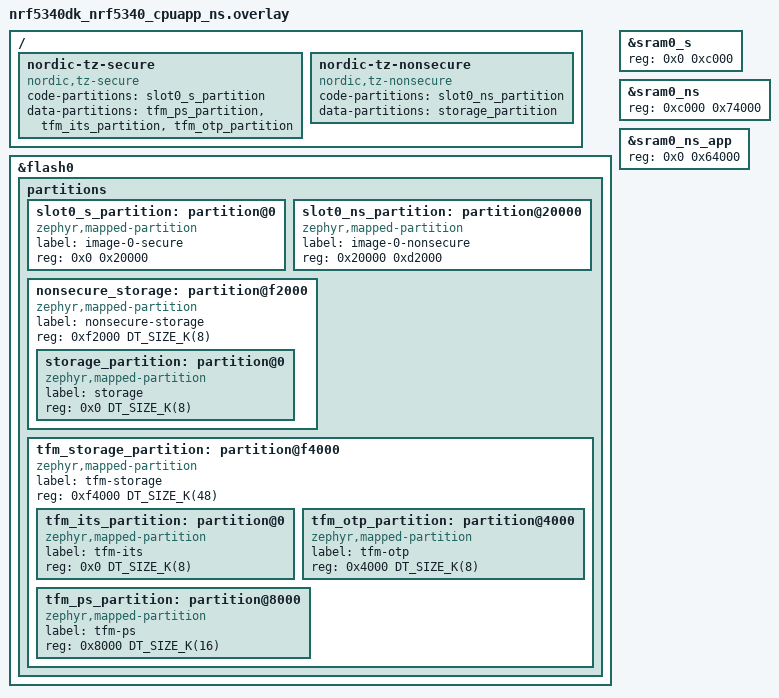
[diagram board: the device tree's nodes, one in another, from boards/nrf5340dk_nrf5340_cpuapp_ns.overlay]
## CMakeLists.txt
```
#
# Copyright (c) 2018 Nordic Semiconductor
#
# SPDX-License-Identifier: LicenseRef-Nordic-5-Clause
#
cmake_minimum_required(VERSION 3.20.0)

find_package(Zephyr REQUIRED HINTS $ENV{ZEPHYR_BASE})
project(NONE)

# NORDIC SDK APP START
target_sources(app PRIVATE
  src/main.c
)

# NORDIC SDK APP END
```

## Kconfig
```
#
# Copyright (c) 2018 Nordic Semiconductor
#
# SPDX-License-Identifier: LicenseRef-Nordic-5-Clause
#

source "Kconfig.zephyr"

menu "Nordic LED-Button BLE GATT service sample"

config BT_LBS_SECURITY_ENABLED
	bool "Enable security"
	default y
	select BT_SMP
	select BT_SETTINGS
	select FLASH
	select FLASH_PAGE_LAYOUT
	select FLASH_MAP
	select ZMS if (SOC_FLASH_NRF_RRAM || SOC_FLASH_NRF_MRAM)
	select NVS if !(SOC_FLASH_NRF_RRAM || SOC_FLASH_NRF_MRAM)
	select SETTINGS
	help
	  "Enable BLE security for the LED-Button service"

endmenu
```

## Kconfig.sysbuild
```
#
# Copyright (c) 2023 Nordic Semiconductor
#
# SPDX-License-Identifier: LicenseRef-Nordic-5-Clause
#

config PARTITION_MANAGER
	default y if BOARD_THINGY53

config NRF_RADIO_LOADER
	default y if SOC_NRF54H20

config NRF_DEFAULT_IPC_RADIO
	default y

config NETCORE_IPC_RADIO_BT_HCI_IPC
	default y

source "share/sysbuild/Kconfig"
```

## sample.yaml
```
sample:
  description: Bluetooth Low Energy LED Button service sample
  name: Bluetooth LE LED Button service

common:
  sysbuild: true
  build_only: true
  tags:
    - bluetooth
    - ci_build
    - sysbuild
    - ci_samples_bluetooth

tests:
  sample.bluetooth.peripheral_lbs:
    build_only: false
    platform_allow: &peripheral_lbs_platforms
      - nrf5340dk/nrf5340/cpuapp
      - nrf5340dk/nrf5340/cpuapp/ns
      - nrf54h20dk/nrf54h20/cpuapp
      - nrf54l15dk/nrf54l05/cpuapp
      - nrf54l15dk/nrf54l10/cpuapp
      - nrf54l15dk/nrf54l15/cpuapp
      - nrf54l15dk/nrf54l15/cpuapp/ns
      - nrf54lm20dk/nrf54lm20a/cpuapp
      - nrf54lm20dk/nrf54lm20a/cpuapp/ns
      - nrf54lm20dk/nrf54lm20b/cpuapp
      - nrf54lm20dk/nrf54lm20b/cpuapp/ns
      - nrf54lv10dk/nrf54lv10a/cpuapp
      - nrf54lv10dk/nrf54lv10a/cpuapp/ns
      - nrf54lc10dk/nrf54lc10a/cpuapp
      - nrf54lc10dk/nrf54lc10a/cpuapp/ns
      - nrf54ls05dk/nrf54ls05a/cpuapp
      - nrf54ls05dk/nrf54ls05b/cpuapp
      - nrf7120dk/nrf7120/cpuapp
    integration_platforms: *peripheral_lbs_platforms
    harness: console
    harness_config:
      type: multi_line
      ordered: true
      regex:
        - "Starting Bluetooth Peripheral LBS sample"
        - "Bluetooth initialized"
        - "Advertising successfully started"
    timeout: 15

  sample.bluetooth.peripheral_lbs_minimal:
    platform_allow:
      - nrf54ls05dk/nrf54ls05a/cpuapp
    integration_platforms:
      - nrf54ls05dk/nrf54ls05a/cpuapp
    extra_args: FILE_SUFFIX=minimal

  sample.bluetooth.peripheral_lbs_no_security:
    platform_allow: *peripheral_lbs_platforms
    integration_platforms:
      - nrf54l15dk/nrf54l15/cpuapp
    extra_args: CONFIG_BT_LBS_SECURITY_ENABLED=n

  sample.bluetooth.peripheral_lbs_bt_ota_dfu:
    build_only: true
    platform_allow:
      - nrf5340dk/nrf5340/cpuapp
      - nrf5340dk/nrf5340/cpuapp/ns
      - nrf54l15dk/nrf54l05/cpuapp
      - nrf54l15dk/nrf54l10/cpuapp
      - nrf54l15dk/nrf54l15/cpuapp
      - nrf54l15dk/nrf54l15/cpuapp/ns
      - nrf54lm20dk/nrf54lm20a/cpuapp
      - nrf54lm20dk/nrf54lm20a/cpuapp/ns
      - nrf54lm20dk/nrf54lm20b/cpuapp
      - nrf54lm20dk/nrf54lm20b/cpuapp/ns
      - nrf54lv10dk/nrf54lv10a/cpuapp
      - nrf54lv10dk/nrf54lv10a/cpuapp/ns
      - nrf54lc10dk/nrf54lc10a/cpuapp
      - nrf54lc10dk/nrf54lc10a/cpuapp/ns
      - nrf54ls05dk/nrf54ls05a/cpuapp
      - nrf54ls05dk/nrf54ls05b/cpuapp
    integration_platforms:
      - nrf5340dk/nrf5340/cpuapp
      - nrf54l15dk/nrf54l05/cpuapp
      - nrf54l15dk/nrf54l10/cpuapp
      - nrf54l15dk/nrf54l15/cpuapp
      - nrf54l15dk/nrf54l15/cpuapp/ns
      - nrf54lm20dk/nrf54lm20a/cpuapp
      - nrf54lm20dk/nrf54lm20a/cpuapp/ns
      - nrf54lm20dk/nrf54lm20b/cpuapp
      - nrf54lm20dk/nrf54lm20b/cpuapp/ns
      - nrf54lv10dk/nrf54lv10a/cpuapp
      - nrf54lv10dk/nrf54lv10a/cpuapp/ns
      - nrf54lc10dk/nrf54lc10a/cpuapp
      - nrf54lc10dk/nrf54lc10a/cpuapp/ns
      - nrf54ls05dk/nrf54ls05a/cpuapp
      - nrf54ls05dk/nrf54ls05b/cpuapp
    extra_configs:
      - CONFIG_BOOTLOADER_MCUBOOT=y
      - CONFIG_NCS_SAMPLE_MCUMGR_BT_OTA_DFU=y

  sample.bluetooth.peripheral_lbs_bt_ota_dfu.direct_xip:
    build_only: true
    platform_allow:
      - nrf54l15dk/nrf54l15/cpuapp
    integration_platforms:
      - nrf54l15dk/nrf54l15/cpuapp
    extra_args: mcuboot_CONFIG_BOOT_DIRECT_XIP=y
    extra_configs:
      - CONFIG_BOOTLOADER_MCUBOOT=y
      - CONFIG_NCS_SAMPLE_MCUMGR_BT_OTA_DFU=y
      - CONFIG_MCUBOOT_BOOTLOADER_MODE_DIRECT_XIP=y

  sample.bluetooth.peripheral_lbs_bt_ota_dfu.direct_xip.revert:
    build_only: true
    platform_allow:
      - nrf54l15dk/nrf54l15/cpuapp
    integration_platforms:
      - nrf54l15dk/nrf54l15/cpuapp
    extra_args:
      - mcuboot_CONFIG_BOOT_DIRECT_XIP=y
      - mcuboot_CONFIG_BOOT_DIRECT_XIP_REVERT=y
    extra_configs:
      - CONFIG_BOOTLOADER_MCUBOOT=y
      - CONFIG_NCS_SAMPLE_MCUMGR_BT_OTA_DFU=y
      - CONFIG_MCUBOOT_BOOTLOADER_MODE_DIRECT_XIP_WITH_REVERT=y

  sample.bluetooth.peripheral_lbs.llvm:
    toolchain_allow: llvm
    platform_allow:
      - nrf54l15dk/nrf54l15/cpuapp
      - nrf54l15dk/nrf54l15/cpuapp/ns
      - nrf54lm20dk/nrf54lm20a/cpuapp
      - nrf54lm20dk/nrf54lm20a/cpuapp/ns
      - nrf54lm20dk/nrf54lm20b/cpuapp
      - nrf54lm20dk/nrf54lm20b/cpuapp/ns
      - nrf54lv10dk/nrf54lv10a/cpuapp
      - nrf54lc10dk/nrf54lc10a/cpuapp
      - nrf54ls05dk/nrf54ls05a/cpuapp
      - nrf54ls05dk/nrf54ls05b/cpuapp
    integration_platforms:
      - nrf54l15dk/nrf54l15/cpuapp
      - nrf54l15dk/nrf54l15/cpuapp/ns
      - nrf54lm20dk/nrf54lm20a/cpuapp
      - nrf54lm20dk/nrf54lm20a/cpuapp/ns
      - nrf54lm20dk/nrf54lm20b/cpuapp
      - nrf54lm20dk/nrf54lm20b/cpuapp/ns
      - nrf54lv10dk/nrf54lv10a/cpuapp
      - nrf54lc10dk/nrf54lc10a/cpuapp
      - nrf54ls05dk/nrf54ls05a/cpuapp
      - nrf54ls05dk/nrf54ls05b/cpuapp
    tags:
      - bluetooth
      - ci_build
      - sysbuild

  sample.bluetooth.peripheral_lbs.l15_tag:
    integration_platforms:
      - nrf54l15tag/nrf54l15/cpuapp
    platform_allow:
      - nrf54l15tag/nrf54l15/cpuapp
    extra_configs:
      - CONFIG_NCS_SAMPLE_MCUMGR_BT_OTA_DFU=y
      - CONFIG_LOG_BACKEND_UART=n
      - CONFIG_UART_CONSOLE=n
      - CONFIG_USE_SEGGER_RTT=y
      - CONFIG_LOG_BACKEND_RTT=y
      - CONFIG_LOG_MODE_DEFERRED=y
      - CONFIG_LOG_BACKEND_UART=n
      - CONFIG_SEGGER_RTT_MAX_NUM_UP_BUFFERS=5
      - CONFIG_SEGGER_RTT_MAX_NUM_DOWN_BUFFERS=5
      - CONFIG_SEGGER_RTT_BUFFER_SIZE_UP=2048
      - CONFIG_SEGGER_RTT_BUFFER_SIZE_DOWN=32
      - CONFIG_SEGGER_RTT_PRINTF_BUFFER_SIZE=128
    extra_args:
      - SB_CONFIG_BOOTLOADER_MCUBOOT=y
      - mcuboot_CONFIG_LOG_BACKEND_UART=n
      - mcuboot_CONFIG_UART_CONSOLE=n
      - mcuboot_CONFIG_USE_SEGGER_RTT=y
      - mcuboot_CONFIG_LOG_BACKEND_RTT=y
      - mcuboot_CONFIG_LOG_MODE_IMMEDIATE=y
      - mcuboot_CONFIG_LOG_BACKEND_UART=n
```

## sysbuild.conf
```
#
# Copyright (c) 2024 Nordic Semiconductor
#
# SPDX-License-Identifier: LicenseRef-Nordic-5-Clause
#

SB_CONFIG_BT=y
#SB_CONFIG_BT_RPC
#SB_CONFIG_IEEE802154

#SB_CONFIG_NETCORE_IPC_RADIO_CUSTOM_CONF
#SB_CONFIG_NETCORE_IPC_RADIO_DEBUG
```

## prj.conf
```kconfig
#
# Copyright (c) 2018 Nordic Semiconductor
#
# SPDX-License-Identifier: LicenseRef-Nordic-5-Clause
#
CONFIG_NCS_SAMPLES_DEFAULTS=y

CONFIG_BT=y
CONFIG_BT_PERIPHERAL=y
CONFIG_BT_DEVICE_NAME="Nordic_LBS"

# Enable the LBS service
CONFIG_BT_LBS=y
CONFIG_BT_LBS_POLL_BUTTON=y
CONFIG_DK_LIBRARY=y

CONFIG_SYSTEM_WORKQUEUE_STACK_SIZE=2048

# Enable old clock_control_nrf api implementation for mpsl to use
CONFIG_CLOCK_CONTROL_NRF=y
```

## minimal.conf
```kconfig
# BEGIN Configurations from basic/minimal
# Drivers and peripherals
CONFIG_I2C=n
CONFIG_WATCHDOG=n
CONFIG_GPIO=n
CONFIG_PINMUX=n
CONFIG_SPI=n
CONFIG_SERIAL=n

# Power management
CONFIG_PM=n

# Interrupts
CONFIG_DYNAMIC_INTERRUPTS=n
CONFIG_IRQ_OFFLOAD=n

# Memory protection
CONFIG_THREAD_STACK_INFO=n
CONFIG_THREAD_CUSTOM_DATA=n
CONFIG_FPU=n

# Boot
CONFIG_BOOT_BANNER=n
CONFIG_BOOT_DELAY=0

# Console
CONFIG_CONSOLE=n
CONFIG_UART_CONSOLE=n
CONFIG_STDOUT_CONSOLE=n
CONFIG_PRINTK=n
CONFIG_EARLY_CONSOLE=n

# Build
CONFIG_SIZE_OPTIMIZATIONS=y

# ARM
CONFIG_ARM_MPU=n
# END Configurations from basic/minimal

# In order to correctly tune the stack sizes for the threads the following
# Configurations can enabled to print the current use:
# CONFIG_THREAD_NAME=y
# CONFIG_THREAD_ANALYZER=y
# CONFIG_THREAD_ANALYZER_AUTO=y
# CONFIG_THREAD_ANALYZER_RUN_UNLOCKED=y
# CONFIG_THREAD_ANALYZER_USE_PRINTK=y
# CONFIG_CONSOLE=y
# CONFIG_UART_CONSOLE=y
# CONFIG_SERIAL=y
# CONFIG_PRINTK=y

# Example output of thread analyzer
# SDC RX              : unused 816 usage 208 / 1024 (20 %)
# BT RX               : unused 1784 usage 416 / 2200 (18 %)
# BT TX               : unused 992 usage 544 / 1536 (35 %)
# thread_analyzer     : unused 136 usage 376 / 512 (73 %)
# sysworkq            : unused 1824 usage 224 / 2048 (10 %)
# MPSL signal         : unused 520 usage 504 / 1024 (49 %)
# idle 00             : unused 192 usage 64 / 256 (25 %)
# main                : unused 136 usage 888 / 1024 (86 %)
# Configurations set based on thread analyzer output.
CONFIG_SDC_RX_STACK_SIZE=324
CONFIG_BT_RX_STACK_SIZE=1024
CONFIG_BT_HCI_TX_STACK_SIZE_WITH_PROMPT=y
CONFIG_BT_HCI_TX_STACK_SIZE=640
CONFIG_SYSTEM_WORKQUEUE_STACK_SIZE=256
CONFIG_MPSL_SIGNAL_STACK_SIZE=640
CONFIG_MAIN_STACK_SIZE=1024
CONFIG_IDLE_STACK_SIZE=128
CONFIG_ISR_STACK_SIZE=1024

# Disable features not needed
CONFIG_TIMESLICING=n
CONFIG_MINIMAL_LIBC_MALLOC=n
CONFIG_LOG=n
CONFIG_ASSERT=n

# Disable Bluetooth features not needed
CONFIG_BT_DEBUG_NONE=y
CONFIG_BT_ASSERT=n
CONFIG_BT_DATA_LEN_UPDATE=n
CONFIG_BT_PHY_UPDATE=n
CONFIG_BT_GATT_CACHING=n
CONFIG_BT_GATT_SERVICE_CHANGED=n
CONFIG_BT_GAP_PERIPHERAL_PREF_PARAMS=n
CONFIG_BT_SETTINGS_CCC_LAZY_LOADING=y
CONFIG_BT_HCI_VS_EXT=n

# Disable Bluetooth controller features not needed
CONFIG_BT_CTLR_PRIVACY=n
CONFIG_BT_CTLR_PHY_2M=n

# Reduce Bluetooth buffers
CONFIG_BT_DISCARDABLE_BUF_COUNT=1
CONFIG_BT_DISCARDABLE_BUF_SIZE=45
CONFIG_BT_RX_BUF_COUNT=2

CONFIG_BT_CONN_TX_MAX=2
CONFIG_BT_L2CAP_TX_BUF_COUNT=2
CONFIG_BT_ATT_TX_MAX=1
CONFIG_BT_CTLR_RX_BUFFERS=1
CONFIG_BT_CTLR_TX_BUFFERS=3
CONFIG_BT_CTLR_TX_BUFFER_SIZE=27
```

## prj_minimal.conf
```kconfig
# BEGIN Configurations from basic/minimal

CONFIG_NCS_SAMPLES_DEFAULTS=y

CONFIG_BT=y
CONFIG_BT_PERIPHERAL=y
CONFIG_BT_DEVICE_NAME="Nordic_LBS"

# Enable the LBS service
CONFIG_BT_LBS=y
CONFIG_BT_LBS_POLL_BUTTON=y
CONFIG_DK_LIBRARY=y

# Drivers and peripherals
CONFIG_I2C=n
CONFIG_WATCHDOG=n
CONFIG_GPIO=n
CONFIG_SPI=n
CONFIG_SERIAL=n

# Power management

# Interrupts
CONFIG_DYNAMIC_INTERRUPTS=n
CONFIG_IRQ_OFFLOAD=n

# Memory protection
CONFIG_THREAD_STACK_INFO=n
CONFIG_THREAD_CUSTOM_DATA=n
CONFIG_FPU=n

# Boot
CONFIG_NCS_BOOT_BANNER=n
CONFIG_BOOT_BANNER=n
CONFIG_BOOT_DELAY=0

# Console
CONFIG_CONSOLE=n
CONFIG_UART_CONSOLE=n
CONFIG_STDOUT_CONSOLE=n
CONFIG_PRINTK=n
CONFIG_EARLY_CONSOLE=n

# Build
CONFIG_SIZE_OPTIMIZATIONS=y

# ARM
CONFIG_ARM_MPU=n
# END Configurations from basic/minimal

# In order to correctly tune the stack sizes for the threads the following
# Configurations can enabled to print the current use:
# CONFIG_THREAD_NAME=y
# CONFIG_THREAD_ANALYZER=y
# CONFIG_THREAD_ANALYZER_AUTO=y
# CONFIG_THREAD_ANALYZER_RUN_UNLOCKED=y
# CONFIG_THREAD_ANALYZER_USE_PRINTK=y
# CONFIG_CONSOLE=y
# CONFIG_UART_CONSOLE=y
# CONFIG_SERIAL=y
# CONFIG_PRINTK=y

# Example output of thread analyzer
# SDC RX              : unused 816 usage 208 / 1024 (20 %)
# BT RX               : unused 1784 usage 416 / 2200 (18 %)
# BT TX               : unused 992 usage 544 / 1536 (35 %)
# thread_analyzer     : unused 136 usage 376 / 512 (73 %)
# sysworkq            : unused 1824 usage 224 / 2048 (10 %)
# MPSL signal         : unused 520 usage 504 / 1024 (49 %)
# idle 00             : unused 192 usage 64 / 256 (25 %)
# main                : unused 136 usage 888 / 1024 (86 %)
# Configurations set based on thread analyzer output.
CONFIG_BT_RX_STACK_SIZE=1024
CONFIG_BT_HCI_TX_STACK_SIZE_WITH_PROMPT=y
CONFIG_BT_HCI_TX_STACK_SIZE=640
CONFIG_SYSTEM_WORKQUEUE_STACK_SIZE=1536
CONFIG_MPSL_WORK_STACK_SIZE=640
CONFIG_IDLE_STACK_SIZE=128
CONFIG_ISR_STACK_SIZE=1024

# Disable features not needed
CONFIG_TIMESLICING=n
CONFIG_COMMON_LIBC_MALLOC=n
CONFIG_LOG=n
CONFIG_ASSERT=n

# Disable Bluetooth features not needed
CONFIG_BT_DEBUG_NONE=y
CONFIG_BT_ASSERT=n
CONFIG_BT_DATA_LEN_UPDATE=n
CONFIG_BT_PHY_UPDATE=n
CONFIG_BT_GATT_CACHING=n
CONFIG_BT_GATT_SERVICE_CHANGED=n
CONFIG_BT_GAP_PERIPHERAL_PREF_PARAMS=n
CONFIG_BT_SETTINGS_CCC_LAZY_LOADING=y
CONFIG_BT_HCI_VS=n

# Disable Bluetooth controller features not needed
CONFIG_BT_CTLR_PRIVACY=n
CONFIG_BT_CTLR_PHY_2M=n

# Reduce Bluetooth buffers
CONFIG_BT_BUF_EVT_DISCARDABLE_COUNT=1
CONFIG_BT_BUF_EVT_DISCARDABLE_SIZE=43
CONFIG_BT_BUF_EVT_RX_COUNT=2

CONFIG_BT_L2CAP_TX_BUF_COUNT=2
CONFIG_BT_ATT_TX_COUNT=2
CONFIG_BT_BUF_EVT_RX_COUNT=4
CONFIG_BT_BUF_ACL_TX_COUNT=3
CONFIG_BT_BUF_ACL_TX_SIZE=27
```

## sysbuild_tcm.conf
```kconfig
#
# Copyright (c) 2025 Nordic Semiconductor ASA
#
# SPDX-License-Identifier: LicenseRef-Nordic-5-Clause
#

# ipc_radio in cpurad TCM via radio_loader; no MCUboot (no signed merge, no DFU).
SB_CONFIG_LBS_IPC_RADIO_TCM=y
SB_CONFIG_NETCORE_REMOTE=y
SB_CONFIG_NRF_RADIO_LOADER=y

SB_CONFIG_BOOTLOADER_NONE=y
SB_CONFIG_BOOTLOADER_MCUBOOT=n
```

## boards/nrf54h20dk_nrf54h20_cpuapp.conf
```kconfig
#
# Copyright (c) 2025 Nordic Semiconductor ASA
#
# SPDX-License-Identifier: LicenseRef-Nordic-5-Clause
#

# Enable device power management
CONFIG_PM_DEVICE=y
CONFIG_PM_DEVICE_RUNTIME=y

# Enable system power management
CONFIG_PM=y

# Enable power off state
CONFIG_POWEROFF=y

# Enable cpurad for sysbuild
CONFIG_SOC_NRF54H20_CPURAD_ENABLE=y

# MRAM latency optimization - allow MRAM to power off when idle
# This reduces power consumption by allowing MRAM power gating
# CONFIG_MRAM_LATENCY defaults to n, which allows MRAM power gating
CONFIG_MRAM_LATENCY_AUTO_REQ=n

# Peak Current Management
CONFIG_MPSL_FORCE_RRAM_ON_ALL_THE_TIME=n
```

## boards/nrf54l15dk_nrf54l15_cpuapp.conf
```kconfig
#
# Copyright (c) 2025 Nordic Semiconductor ASA
#
# SPDX-License-Identifier: LicenseRef-Nordic-5-Clause
#

CONFIG_MAIN_STACK_SIZE=4096
```

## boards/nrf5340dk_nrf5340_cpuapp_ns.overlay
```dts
/*
 * Copyright (c) 2026 Nordic Semiconductor ASA
 *
 * SPDX-License-Identifier: LicenseRef-Nordic-5-Clause
 */

/delete-node/ &boot_partition;
/delete-node/ &slot0_partition;
/delete-node/ &slot1_partition;
/delete-node/ &tfm_its_partition;
/delete-node/ &tfm_otp_partition;
/delete-node/ &tfm_ps_partition;
/delete-node/ &storage_partition;

&flash0 {
	partitions {
		slot0_s_partition: partition@0 {
			compatible = "zephyr,mapped-partition";
			label = "image-0-secure";
			reg = <0x0 0x20000>;
		};

		slot0_ns_partition: partition@20000 {
			compatible = "zephyr,mapped-partition";
			label = "image-0-nonsecure";
			reg = <0x20000 0xd2000>;
		};

		nonsecure_storage: partition@f2000 {
			compatible = "zephyr,mapped-partition";
			label = "nonsecure-storage";
			reg = <0xf2000 DT_SIZE_K(8)>;
			ranges = <0x0 0xf2000 DT_SIZE_K(8)>;
			#address-cells = <1>;
			#size-cells = <1>;

			storage_partition: partition@0 {
				compatible = "zephyr,mapped-partition";
				label = "storage";
				reg = <0x0 DT_SIZE_K(8)>;
			};
		};

		tfm_storage_partition: partition@f4000 {
			compatible = "zephyr,mapped-partition";
			label = "tfm-storage";
			reg = <0xf4000 DT_SIZE_K(48)>;
			ranges = <0x0 0xf4000 DT_SIZE_K(48)>;
			#address-cells = <1>;
			#size-cells = <1>;

			tfm_its_partition: partition@0 {
				compatible = "zephyr,mapped-partition";
				label = "tfm-its";
				reg = <0x0 DT_SIZE_K(8)>;
			};

			tfm_otp_partition: partition@4000 {
				compatible = "zephyr,mapped-partition";
				label = "tfm-otp";
				reg = <0x4000 DT_SIZE_K(8)>;
			};

			tfm_ps_partition: partition@8000 {
				compatible = "zephyr,mapped-partition";
				label = "tfm-ps";
				reg = <0x8000 DT_SIZE_K(16)>;
			};
		};
	};
};

/*
 * TrustZone SRAM split from devicetree (region_defs.h for TF-M). The secure image uses
 * 48 KiB (0xc000) at the base of cpuapp SRAM (&sram0_s); NS RAM begins at 0x20000000 + 0xc000.
 * &sram0_ns spans 0x74000 bytes; &sram0_ns_app is 0x64000 because the top 0x10000 (64 KiB)
 * within that NS window is sram0_shared for application/network-core IPC
 * (nrf5340_shared_sram_partition.dtsi), i.e. 0x64000 + 0x10000 == 0x74000.
 */
&sram0_s {
	reg = <0x0 0xc000>;
};

&sram0_ns {
	reg = <0xc000 0x74000>;
	ranges = <0x0 0xc000 0x74000>;
};

&sram0_ns_app {
	reg = <0x0 0x64000>;
};

/ {
	/delete-node/ nordic-tz-secure;
	/delete-node/ nordic-tz-nonsecure;

	nordic-tz-secure {
		compatible = "nordic,tz-secure";
		code-partitions = <&slot0_s_partition>;
		data-partitions = <&tfm_ps_partition>,
				  <&tfm_its_partition>,
				  <&tfm_otp_partition>;
	};

	nordic-tz-nonsecure {
		compatible = "nordic,tz-nonsecure";
		code-partitions = <&slot0_ns_partition>;
		data-partitions = <&storage_partition>;
	};
};
```

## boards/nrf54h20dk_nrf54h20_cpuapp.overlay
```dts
/*
 * Copyright (c) 2025 Nordic Semiconductor ASA
 *
 * SPDX-License-Identifier: LicenseRef-Nordic-5-Clause
 */

#include "../common/memory_map_tcm.dtsi"

/* Disable unused peripherals to reduce power consumption */
&usbhs {
	status = "disabled";
};

&canpll {
	status = "disabled";
};

&can120 {
	status = "disabled";
};

&adc {
	status = "disabled";
};

&pwm130 {
	status = "disabled";
};

&cpuapp_ieee802154 {
	status = "disabled";
};

&exmif {
	status = "disabled";
};

&uart120 {
	status = "disabled";
};

&uart135 {
	status = "disabled";
};

/* Enable PM runtime for uart136 (console UART) */
&uart136 {
	zephyr,pm-device-runtime-auto;
};
```

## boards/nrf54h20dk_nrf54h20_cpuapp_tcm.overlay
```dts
/*
 * Copyright (c) 2025 Nordic Semiconductor ASA
 *
 * SPDX-License-Identifier: LicenseRef-Nordic-5-Clause
 */

/* CPURAD TCM memory map for FILE_SUFFIX=tcm (no MCUboot). */
#include "../common/memory_map_tcm.dtsi"
```

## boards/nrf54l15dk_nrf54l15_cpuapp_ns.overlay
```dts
/*
 * Copyright (c) 2026 Nordic Semiconductor ASA
 *
 * SPDX-License-Identifier: LicenseRef-Nordic-5-Clause
 */

/delete-node/ &storage_partition;
/delete-node/ &slot0_ns_partition;
/delete-node/ &tfm_its_partition;
/delete-node/ &tfm_otp_partition;
/delete-node/ &tfm_ps_partition;

&cpuapp_rram {
	partitions {
		slot0_s_partition: partition@0 {
			compatible = "zephyr,mapped-partition";
			label = "image-0-secure";
			reg = <0x0 0x40000>;
		};

		tfm_storage_partition: partition@40000 {
			compatible = "zephyr,mapped-partition";
			label = "tfm-storage";
			reg = <0x40000 DT_SIZE_K(40)>;
			ranges = <0x0 0x40000 DT_SIZE_K(40)>;
			#address-cells = <1>;
			#size-cells = <1>;

			tfm_its_partition: partition@0 {
				compatible = "zephyr,mapped-partition";
				label = "tfm-its";
				reg = <0x0 DT_SIZE_K(16)>;
			};

			tfm_otp_partition: partition@4000 {
				compatible = "zephyr,mapped-partition";
				label = "tfm-otp";
				reg = <0x4000 DT_SIZE_K(8)>;
			};

			tfm_ps_partition: partition@6000 {
				compatible = "zephyr,mapped-partition";
				label = "tfm-ps";
				reg = <0x6000 DT_SIZE_K(16)>;
			};
		};

		slot0_ns_partition: partition@4a000 {
			compatible = "zephyr,mapped-partition";
			label = "image-0-nonsecure";
			reg = <0x4a000 0x131000>;
		};

		nonsecure_storage: partition@17b000 {
			compatible = "zephyr,mapped-partition";
			label = "nonsecure-storage";
			reg = <0x17b000 DT_SIZE_K(8)>;
			ranges = <0x0 0x17b000 DT_SIZE_K(8)>;
			#address-cells = <1>;
			#size-cells = <1>;

			storage_partition: partition@0 {
				compatible = "zephyr,mapped-partition";
				label = "storage";
				reg = <0x0 DT_SIZE_K(8)>;
			};
		};
	};
};
```

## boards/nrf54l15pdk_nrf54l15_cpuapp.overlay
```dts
/*
 * Copyright (c) 2024 Nordic Semiconductor ASA
 *
 * SPDX-License-Identifier: LicenseRef-Nordic-5-Clause
 */

/*
 * The sample does not use Buttons 3 and 4.
 * Buttons 3 and 4 in PDK are connected to the GPIO port, which does not support interrupts.
 */

/ {
	aliases {
		/delete-property/ sw2;
		/delete-property/ sw3;
	};
	buttons {
		/delete-node/ button_2;
		/delete-node/ button_3;
	};
};
```

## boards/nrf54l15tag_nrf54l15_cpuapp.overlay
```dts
/*
 * Copyright (c) 2026 Nordic Semiconductor ASA
 *
 * SPDX-License-Identifier: LicenseRef-Nordic-5-Clause
 */

/delete-node/ &boot_partition;

&cpuapp_rram {
	partitions {
		compatible = "fixed-partitions";
		#address-cells = <1>;
		#size-cells = <1>;

		boot_partition: partition@0 {
			label = "mcuboot";
			reg = <0x00000000 0x0000f800>;
		};
	};
};
```

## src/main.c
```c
/*
 * Copyright (c) 2018 Nordic Semiconductor ASA
 *
 * SPDX-License-Identifier: LicenseRef-Nordic-5-Clause
 */

#include <zephyr/types.h>
#include <stddef.h>
#include <string.h>
#include <errno.h>
#include <zephyr/logging/log.h>
#include <zephyr/sys/byteorder.h>
#include <zephyr/kernel.h>
#include <zephyr/drivers/gpio.h>
#include <soc.h>

#include <zephyr/bluetooth/bluetooth.h>
#include <zephyr/bluetooth/hci.h>
#include <zephyr/bluetooth/conn.h>
#include <zephyr/bluetooth/uuid.h>
#include <zephyr/bluetooth/gatt.h>

#include <bluetooth/services/lbs.h>

#include <zephyr/settings/settings.h>

#include <dk_buttons_and_leds.h>

LOG_MODULE_REGISTER(peripheral_lbs, LOG_LEVEL_INF);

#define DEVICE_NAME             CONFIG_BT_DEVICE_NAME
#define DEVICE_NAME_LEN         (sizeof(DEVICE_NAME) - 1)


#define RUN_STATUS_LED          DK_LED1
#define CON_STATUS_LED          DK_LED2
#define RUN_LED_BLINK_INTERVAL  1000

#define USER_LED                DK_LED3

#define USER_BUTTON             DK_BTN1_MSK

static bool app_button_state;
static struct k_work adv_work;

static const struct bt_data ad[] = {
	BT_DATA_BYTES(BT_DATA_FLAGS, (BT_LE_AD_GENERAL | BT_LE_AD_NO_BREDR)),
	BT_DATA(BT_DATA_NAME_COMPLETE, DEVICE_NAME, DEVICE_NAME_LEN),
};

static const struct bt_data sd[] = {
	BT_DATA_BYTES(BT_DATA_UUID128_ALL, BT_UUID_LBS_VAL),
};

static void adv_work_handler(struct k_work *work)
{
	int err = bt_le_adv_start(BT_LE_ADV_CONN_FAST_2, ad, ARRAY_SIZE(ad), sd, ARRAY_SIZE(sd));

	if (err) {
		LOG_WRN("Advertising failed to start (err %d)", err);
		return;
	}

	LOG_INF("Advertising successfully started");
}

static void advertising_start(void)
{
	k_work_submit(&adv_work);
}

static void connected(struct bt_conn *conn, uint8_t err)
{
	if (err) {
		LOG_WRN("Connection failed, err 0x%02x %s", err, bt_hci_err_to_str(err));
		return;
	}

	LOG_INF("Connected");

	dk_set_led_on(CON_STATUS_LED);
}

static void disconnected(struct bt_conn *conn, uint8_t reason)
{
	LOG_INF("Disconnected, reason 0x%02x %s", reason, bt_hci_err_to_str(reason));

	dk_set_led_off(CON_STATUS_LED);
}

static void recycled_cb(void)
{
	LOG_INF("Connection object available from previous conn. Disconnect is complete!");
	advertising_start();
}

#ifdef CONFIG_BT_LBS_SECURITY_ENABLED
static void security_changed(struct bt_conn *conn, bt_security_t level,
			     enum bt_security_err err)
{
	if (!err) {
		LOG_INF("Security changed: %s level %u", bt_addr_le_str(bt_conn_get_dst(conn)),
			level);
	} else {
		LOG_WRN("Security failed: %s level %u err %d %s",
			bt_addr_le_str(bt_conn_get_dst(conn)), level, err,
			bt_security_err_to_str(err));
	}
}
#endif

BT_CONN_CB_DEFINE(conn_callbacks) = {
	.connected        = connected,
	.disconnected     = disconnected,
	.recycled         = recycled_cb,
#ifdef CONFIG_BT_LBS_SECURITY_ENABLED
	.security_changed = security_changed,
#endif
};

#if defined(CONFIG_BT_LBS_SECURITY_ENABLED)
static void auth_passkey_display(struct bt_conn *conn, unsigned int passkey)
{
	LOG_INF("Passkey for %s: %06u", bt_addr_le_str(bt_conn_get_dst(conn)), passkey);
}

static void auth_cancel(struct bt_conn *conn)
{
	LOG_INF("Pairing cancelled: %s", bt_addr_le_str(bt_conn_get_dst(conn)));
}

static void pairing_complete(struct bt_conn *conn, bool bonded)
{
	LOG_INF("Pairing completed: %s, bonded: %d", bt_addr_le_str(bt_conn_get_dst(conn)), bonded);
}

static void pairing_failed(struct bt_conn *conn, enum bt_security_err reason)
{
	LOG_WRN("Pairing failed conn: %s, reason %d %s", bt_addr_le_str(bt_conn_get_dst(conn)),
		reason, bt_security_err_to_str(reason));
}

static struct bt_conn_auth_cb conn_auth_callbacks = {
	.passkey_display = auth_passkey_display,
	.cancel = auth_cancel,
};

static struct bt_conn_auth_info_cb conn_auth_info_callbacks = {
	.pairing_complete = pairing_complete,
	.pairing_failed = pairing_failed
};
#else
static struct bt_conn_auth_cb conn_auth_callbacks;
static struct bt_conn_auth_info_cb conn_auth_info_callbacks;
#endif

static void app_led_cb(bool led_state)
{
	LOG_INF("LED write received: turning user LED %s", led_state ? "on" : "off");

	dk_set_led(USER_LED, led_state);
}

static bool app_button_cb(void)
{
	LOG_INF("Button read received: state %s", app_button_state ? "pressed" : "released");

	return app_button_state;
}

static struct bt_lbs_cb lbs_callbacs = {
	.led_cb    = app_led_cb,
	.button_cb = app_button_cb,
};

static void button_changed(uint32_t button_state, uint32_t has_changed)
{
	LOG_INF("Button changed: state 0x%08x, changed 0x%08x", button_state, has_changed);

	if (has_changed & USER_BUTTON) {
		uint32_t user_button_state = button_state & USER_BUTTON;

		LOG_INF("User button %s", user_button_state ? "pressed" : "released");

		bt_lbs_send_button_state(user_button_state);
		app_button_state = user_button_state ? true : false;
	}
}

static int init_button(void)
{
	int err;

	err = dk_buttons_init(button_changed);
	if (err) {
		LOG_WRN("Cannot init buttons (err: %d)", err);
	} else {
		LOG_INF("Buttons initialized");
	}

	return err;
}

int main(void)
{
	int blink_status = 0;
	int err;

	LOG_INF("Starting Bluetooth Peripheral LBS sample");

	err = dk_leds_init();
	if (err) {
		LOG_WRN("LEDs init failed (err %d)", err);
		return 0;
	}

	LOG_INF("LEDs initialized");

	err = init_button();
	if (err) {
		LOG_WRN("Button init failed (err %d)", err);
		return 0;
	}

	if (IS_ENABLED(CONFIG_BT_LBS_SECURITY_ENABLED)) {
		err = bt_conn_auth_cb_register(&conn_auth_callbacks);
		if (err) {
			LOG_WRN("Failed to register authorization callbacks.");
			return 0;
		}

		err = bt_conn_auth_info_cb_register(&conn_auth_info_callbacks);
		if (err) {
			LOG_WRN("Failed to register authorization info callbacks.");
			return 0;
		}
	}

	err = bt_enable(NULL);
	if (err) {
		LOG_WRN("Bluetooth init failed (err %d)", err);
		return 0;
	}

	LOG_INF("Bluetooth initialized");

	if (IS_ENABLED(CONFIG_SETTINGS)) {
		settings_load();
	}

	err = bt_lbs_init(&lbs_callbacs);
	if (err) {
		LOG_WRN("Failed to init LBS (err:%d)", err);
		return 0;
	}

	k_work_init(&adv_work, adv_work_handler);
	advertising_start();

	for (;;) {
		dk_set_led(RUN_STATUS_LED, (++blink_status) % 2);
		k_sleep(K_MSEC(RUN_LED_BLINK_INTERVAL));
	}
}
```
